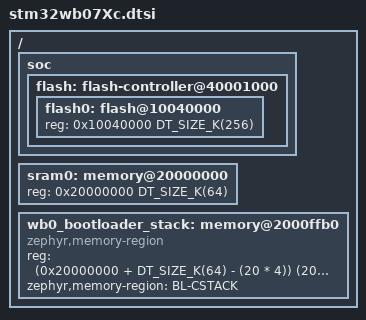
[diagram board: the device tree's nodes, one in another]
/*
 * Copyright (c) 2024 STMicroelectronics
 *
 * SPDX-License-Identifier: Apache-2.0
 */

#include <st/wb0/stm32wb07.dtsi>

/ {
	soc {
		flash: flash-controller@40001000 {
			flash0: flash@10040000 {
				reg = <0x10040000 DT_SIZE_K(256)>;
			};
		};
	};

	sram0: memory@20000000 {
		reg = <0x20000000 DT_SIZE_K(64)>;
	};

	wb0_bootloader_stack: memory@2000ffb0 {
		compatible = "zephyr,memory-region";
		reg = <(0x20000000 + DT_SIZE_K(64) - (20 * 4)) (20 * 4)>;
		zephyr,memory-region = "BL-CSTACK";
	};
};
